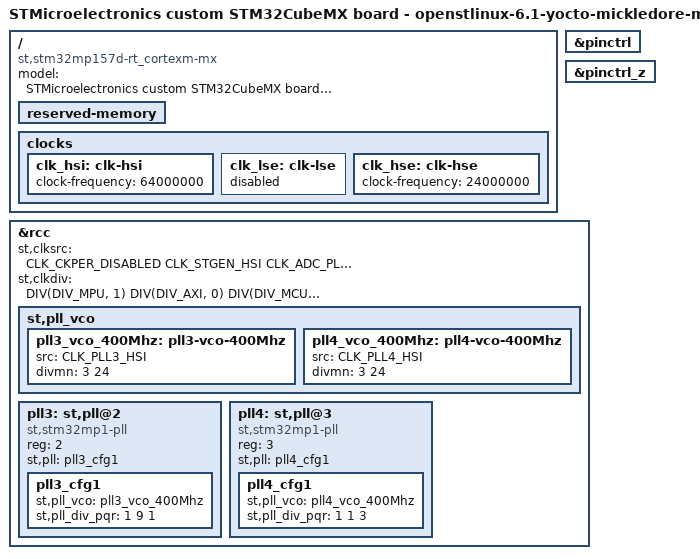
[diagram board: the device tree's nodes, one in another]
// SPDX-License-Identifier: (GPL-2.0-or-later OR BSD-3-Clause)
/*
 * Copyright (C) 2023, STMicroelectronics - All Rights Reserved
 * Author: STM32CubeMX code generation for STMicroelectronics.
 */

/* For more information on Device Tree configuration, please refer to
 * https://wiki.st.com/stm32mpu/wiki/Category:Device_tree_configuration
 */

/dts-v1/;
#include <dt-bindings/pinctrl/stm32-pinfunc.h>
#include <dt-bindings/clock/stm32mp1-clksrc.h>

#include "stm32mp157.dtsi"
#include "stm32mp15xd.dtsi"
#include "stm32mp15xxaa-pinctrl.dtsi"

/* USER CODE BEGIN includes */
/* USER CODE END includes */

/ {
	model = "STMicroelectronics custom STM32CubeMX board - openstlinux-6.1-yocto-mickledore-mp1-v23.06.21";
	compatible = "st,stm32mp157d-rt_cortexm-mx", "st,stm32mp157";

	/* !!! log : Warning - no DDR config found: 'memory' node not generated  !!! */

	/*
	memory@??? {
		reg = < ??? >;
	};
	*/

	reserved-memory {
		#address-cells = <1>;
		#size-cells = <1>;
		ranges;

		/* USER CODE BEGIN reserved-memory */
		/* USER CODE END reserved-memory */
	};

	/* USER CODE BEGIN root */
	/* USER CODE END root */

	clocks {
		/* USER CODE BEGIN clocks */
		/* USER CODE END clocks */

		clk_hsi: clk-hsi {
			clock-frequency = <64000000>;

			/* USER CODE BEGIN clk_hsi */
			/* USER CODE END clk_hsi */
		};
		clk_lse: clk-lse {
			status = "disabled";

			/* USER CODE BEGIN clk_lse */
			/* USER CODE END clk_lse */
		};
		clk_hse: clk-hse {
			clock-frequency = <24000000>;

			/* USER CODE BEGIN clk_hse */
			/* USER CODE END clk_hse */
		};
	};

}; /*root*/

/*Warning: the configuration of the secured GPIOs should be added in (addons) User Section*/
&pinctrl {
	/* USER CODE BEGIN pinctrl */
	/* USER CODE END pinctrl */
};

&pinctrl_z {
	/* USER CODE BEGIN pinctrl_z */
	/* USER CODE END pinctrl_z */
};

&rcc{
	status = "okay";

	/* USER CODE BEGIN rcc */
	/* USER CODE END rcc */

	st,clksrc = <
		CLK_CKPER_DISABLED
		CLK_STGEN_HSI
		CLK_ADC_PLL4R
		CLK_UART35_PCLK1
		CLK_FDCAN_PLL3Q
		CLK_MPU_HSI
		CLK_AXI_HSI
		CLK_MCU_PLL3P
		CLK_RTC_LSI
		CLK_MCO1_DISABLED
		CLK_MCO2_DISABLED
	>;
	st,clkdiv = <
		DIV(DIV_MPU, 1)
		DIV(DIV_AXI, 0)
		DIV(DIV_MCU, 0)
		DIV(DIV_APB1, 1)
		DIV(DIV_APB2, 1)
		DIV(DIV_APB3, 1)
		DIV(DIV_APB4, 0)
		DIV(DIV_APB5, 0)
		DIV(DIV_RTC, 0)
		DIV(DIV_MCO1, 0)
		DIV(DIV_MCO2, 0)
	>;
	st,pll_vco {
		pll3_vco_400Mhz: pll3-vco-400Mhz {
			src = < CLK_PLL3_HSI >;
			divmn = < 3 24 >;
		};
		pll4_vco_400Mhz: pll4-vco-400Mhz {
			src = < CLK_PLL4_HSI >;
			divmn = < 3 24 >;
		};
		/* USER CODE BEGIN rcc_st-pll_vco */
		/* USER CODE END rcc_st-pll_vco */
	};

	pll3:st,pll@2 {
		compatible = "st,stm32mp1-pll";
		reg = <2>;

		st,pll = < &pll3_cfg1 >;

		pll3_cfg1: pll3_cfg1 {
			st,pll_vco = < &pll3_vco_400Mhz >;
			st,pll_div_pqr = < 1 9 1 >;
		};
		/* USER CODE BEGIN pll3 */
		/* USER CODE END pll3 */
	};

	pll4:st,pll@3 {
		compatible = "st,stm32mp1-pll";
		reg = <3>;

		st,pll = < &pll4_cfg1 >;

		pll4_cfg1: pll4_cfg1 {
			st,pll_vco = < &pll4_vco_400Mhz >;
			st,pll_div_pqr = < 1 1 3 >;
		};
		/* USER CODE BEGIN pll4 */
		/* USER CODE END pll4 */
	};

};

/* USER CODE BEGIN addons */
/* USER CODE END addons */

